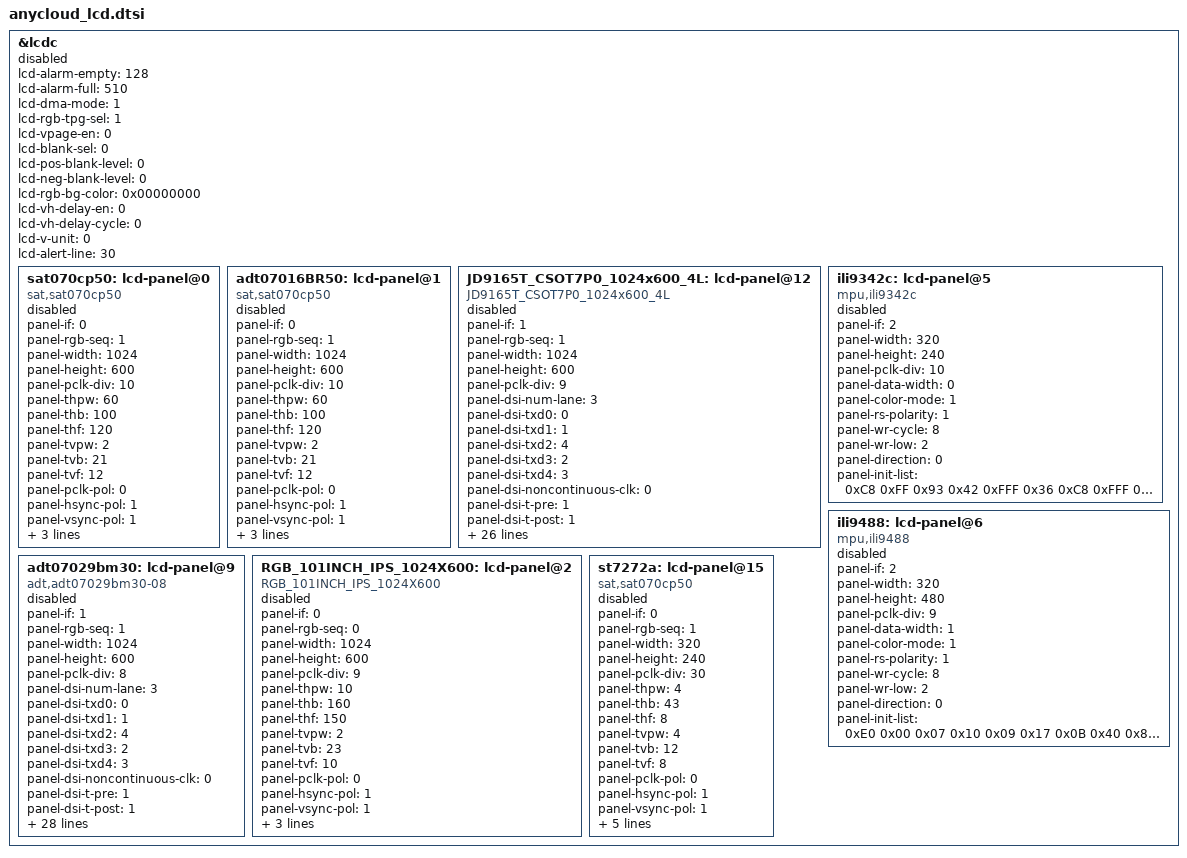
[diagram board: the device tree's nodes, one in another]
/*
 * Anycloud LCD panel dts
 *
 * Copyright (C) 2018 Anyka(Guangzhou) Microelectronics Technology Co., Ltd.
 *
 * Author: Feilong Dong <dong_feilong@anyka.com>
 *
 * This program is free software; you can redistribute it and/or modify
 * it under the terms of the GNU General Public License as published by
 * the Free Software Foundation; either version 2 of the License, or
 * (at your option) any later version.
 *
 * This program is distributed in the hope that it will be useful,
 * but WITHOUT ANY WARRANTY; without even the implied warranty of
 * MERCHANTABILITY or FITNESS FOR A PARTICULAR PURPOSE.  See the
 * GNU General Public License for more details.
 */

&lcdc {
    lcd-alarm-empty = <128>;
    lcd-alarm-full = <510>;
    lcd-dma-mode = <1>;
    //lcd-dummy-seq = <0>; //for 8bit rgb panel set
    //lcd-rgb-seq-sel = <0>;
    //lcd-rgb-odd-seq = <0>;
    //lcd-rgb-even-seq = <0>;
    lcd-rgb-tpg-sel = <1>;
    lcd-vpage-en = <0>; //don't support vpage function in driver
    lcd-blank-sel = <0>;
    lcd-pos-blank-level = <0>;
    lcd-neg-blank-level = <0>;
    lcd-rgb-bg-color = <0x00000000>;
    lcd-vh-delay-en = <0>;
    lcd-vh-delay-cycle = <0>;
    lcd-v-unit = <0>;
    lcd-alert-line = <30>;
    status = "disable";
    
    sat070cp50: lcd-panel@0 { //for RGB panel setting
        compatible = "sat,sat070cp50";
        panel-if = <0>; //0 for RGB, 1 for MIPI, 2 for MPU
        panel-rgb-seq = <1>; //0 for BGR, 1 for RGB
        panel-width = <1024>;
        panel-height = <600>;
        panel-pclk-div = <10>; //pixel clock = Peri_pll/(pclk_div+1)
        panel-thpw = <60>;
        panel-thb = <100>;
        panel-thf = <120>;
        panel-tvpw = <2>;
        panel-tvb = <21>;
        panel-tvf = <12>;
        panel-pclk-pol = <0>; //0:pos, 1:neg
        panel-hsync-pol = <1>;
        panel-vsync-pol = <1>;
        panel-vogate-pol = <0>;
        panel-bus-width = <3>; //0:8bits,1:16bits,2:18bits,3:24bits
        panel-sync-mode = <1>; 

        status = "disable";
    };

    adt07016BR50: lcd-panel@1 { //for AJB RGB panel setting
        compatible = "sat,sat070cp50";
        panel-if = <0>; //0 for RGB, 1 for MIPI, 2 for MPU
        panel-rgb-seq = <1>; //0 for BGR, 1 for RGB
        panel-width = <1024>;
        panel-height = <600>;
        panel-pclk-div = <10>; //pixel clock = Peri_pll/(pclk_div+1)
        panel-thpw = <60>;
        panel-thb = <100>;
        panel-thf = <120>;
        panel-tvpw = <2>;
        panel-tvb = <21>;
        panel-tvf = <12>;
        panel-pclk-pol = <0>; //0:pos, 1:neg
        panel-hsync-pol = <1>;
        panel-vsync-pol = <1>;
        panel-vogate-pol = <0>;
        panel-bus-width = <3>; //0:8bits,1:16bits,2:18bits,3:24bits
        panel-sync-mode = <1>; 

        status = "disable";
    };

    JD9165T_CSOT7P0_1024x600_4L: lcd-panel@12 {
        compatible = "JD9165T_CSOT7P0_1024x600_4L";
        panel-if = <1>; //0 for RGB, 1 for MIPI, 2 for MPU
        panel-rgb-seq = <1>; //0 for BGR, 1 for RGB
        panel-width = <1024>;
        panel-height = <600>;
        panel-pclk-div = <9>; //target pixel clock is about 52MHz when ASIC PLL is 520MHz
        panel-dsi-num-lane = <3>; //0-3: 1lane-4lane
        panel-dsi-txd0 = <0>;
        panel-dsi-txd1 = <1>;
        panel-dsi-txd2 = <4>;
        panel-dsi-txd3 = <2>;
        panel-dsi-txd4 = <3>;
        panel-dsi-noncontinuous-clk = <0>;
        panel-dsi-t-pre = <1>;
        panel-dsi-t-post = <1>;
        panel-dsi-tx-gap = <1>;
        panel-dsi-autoinsert-eotp = <0>;
        panel-dsi-htx-to-count = <0xFFFFFF>;
        panel-dsi-lrx-to-count = <0xFFFFFF>;
        panel-dsi-bta-to-count = <0xFFFFFF>;
        panel-dsi-t-wakeup = <0xc8>;
        panel-dsi-pix-fifo-send-level = <512>;
        panel-dsi-if-color-coding = <0x05>; //24-bit
        panel-dsi-pix-format = <0x03>; //24-bit
        panel-dsi-vsync-pol = <0>;
        panel-dsi-hsync-pol = <0>;
        panel-dsi-video-mode = <0>; //DSI non-burst mode with sync pulses
        panel-dsi-hfp = <100>;
        panel-dsi-hbp = <100>;
        panel-dsi-hsa = <2>;
        panel-dsi-mult-pkts-en = <0>;
        panel-dsi-vbp = <12>;
        panel-dsi-vfp = <95>;
        panel-dsi-vsa = <2>;
        panel-dsi-bllp-mode = <1>;
        panel-dsi-use-null-pkt-bllp = <0>;
        panel-dsi-vc = <0x00>;
        panel-dsi-cmd-type = <0x0>; //0:send init commands in LP mode
        panel-dsi-clk = <400>;
        panel-init-list =
                        <   0x00 0x39 0xDF 0x90 0x85 0x15 0xFFF
                            0x00 0x15 0xDE 0x00 0xFFF
                            0x00 0x15 0xCC 0x37 0xFFF
                            0x00 0x39 0xB2 0x00 0x50 0x50 0xFFF
                            0x00 0x39 0xB6 0x11 0x4F 0x00 0x5F 0x0D 0x16 0xC0 0xEE 0x00 0x5F 0x0D 0x8F 0xFFF
                            0x00 0x39 0xB7 0x00 0xBD 0xBD 0xFFF
                            0x00 0x39 0xBB 0x06 0x67 0x3F 0xFFF
                            0x00 0x39 0xC1 0x40 0x01 0x00 0xFFF
                            0x00 0x39 0xC3 0x0C 0x01 0x00 0x0C 0x18 0xE0 0x78 0x12 0xE8 0xFFF
                            0x00 0x39 0xC4 0x13 0x2C 0x00 0x00 0x00 0x00 0x00 0x00 0x00 0x03 0x22 0xFFF
                            0x00 0x39 0xC8 0x6E 0x69 0x64 0x57 0x4D 0x4E 0x3F 0x46 0x34 0x4E 0x4D 0x4C 0x67 0x54 0x5B 0x4C 0x4B 0x3F 0x2F 0x2B 0x27 0x6E 0x69 0x64 0x57 0x4D 0x4E 0x3F 0x46 0x34 0x4E 0x4D 0x4C 0x67 0x54 0x5B 0x4C 0x4B 0x3F 0x2F 0x2B 0x27 0xFFF
                            0x00 0x39 0xCB 0x71 0xC0 0x00 0xC0 0xC0 0xC0 0x00 0xCB 0x2A 0x00 0x00 0xFFF
                            0x00 0x39 0xCE 0x00 0x50 0x45 0x44 0x44 0x00 0x00 0x0C 0x00 0x00 0x00 0x00 0x00 0x50 0x45 0x44 0x44 0x00 0xFFF
                            0x00 0x39 0xCF 0x00 0x02 0x01 0x02 0x2C 0x02 0x7C 0x03 0x2C 0x00 0x00 0x05 0x7C 0x05 0x2C 0xFFF
                            0x00 0x39 0xD0 0x00 0xE5 0xE5 0xE5 0xE5 0xE5 0xE5 0xDF 0xC6 0xC6 0xD7 0xC4 0xC4 0xD8 0xCA 0xCA 0xE1 0xC8 0xC8 0xD5 0xE5 0xC0 0xDF 0xFFF
                            0x00 0x39 0xD1 0x00 0xE5 0xE5 0xE5 0xE5 0xE5 0xE5 0xDF 0xC7 0xC7 0xD7 0xC5 0xC5 0xD8 0xCB 0xCB 0xE1 0xC9 0xC9 0xD5 0xE5 0xC1 0xDF 0xFFF
                            0x00 0x39 0xD2 0x00 0x25 0x25 0x25 0x25 0x25 0x25 0x1F 0x09 0x09 0x17 0x0B 0x0B 0x18 0x05 0x05 0x21 0x07 0x07 0x1F 0x25 0x01 0x15 0xFFF
                            0x00 0x39 0xD3 0x00 0x25 0x25 0x25 0x25 0x25 0x25 0x1F 0x08 0x08 0x17 0x0A 0x0A 0x18 0x04 0x04 0x21 0x06 0x06 0x1F 0x25 0x00 0x15 0xFFF
                            0x00 0x39 0xD4 0x30 0x00 0x00 0x14 0x00 0x00 0x00 0x00 0x00 0x00 0x00 0x05 0x02 0x00 0x11 0x80 0x00 0xC0 0x04 0x00 0x00 0x00 0x00 0x00 0x00 0x00 0x01 0x01 0x11 0x80 0x0A 0xC0 0x05 0x07 0x01 0x00 0x0B 0x04 0x0A 0x04 0xC8 0xFFF
                            0x00 0x39 0xD5 0x02 0x14 0x01 0x00 0x00 0x00 0x00 0x00 0x00 0x72 0x00 0x17 0x08 0x71 0x00 0x04 0x18 0x1E 0x01 0x09 0x00 0x09 0xFFF
                            0x00 0x39 0xD6 0x04 0x02 0x04 0x02 0x04 0x04 0x04 0x04 0x04 0x02 0x04 0x04 0xFFF
                            0x00 0x15 0xDE 0x02 0xFFF
                            0x00 0x39 0xC5 0x4A 0x00 0xFFF
                            0x00 0x39 0xD0 0x00 0x00 0x11 0x00 0x11 0x26 0x4A 0xEC 0x10 0x59 0x8D 0x26 0x4A 0xEC 0x10 0x59 0x8D 0x00 0x66 0xDD 0x66 0xDD 0xEA 0x86 0x20 0xDC 0x95 0x41 0xEA 0x86 0x20 0xDC 0x95 0x41 0xFFF
                            0x00 0x39 0xD6 0x01 0x01 0x00 0x04 0x00 0x5A 0x00 0x03 0xFFF
                            0x00 0x15 0xDE 0x04 0xFFF
                            0x00 0x39 0xB0 0x44 0x01 0xFFF
                            0x00 0x15 0xDE 0x00 0xFFF
                            0x78 0x05 0x11 0x00 0xFFF
                            0x78 0x05 0x29 0x00 0xFFF>;
        status = "disable";
    };

    // sat101at40: lcd-panel@3 { //for JD9364 MIPI panel setting
    //     compatible = "sat,sat101at40";
    //     panel-if = <1>; //0 for RGB, 1 for MIPI, 2 for MPU
    //     panel-rgb-seq = <1>; //0 for BGR, 1 for RGB
    //     panel-width = <800>;
    //     panel-height = <1280>;
    //     panel-pclk-div = <8>; //pixel clock = Peri_pll/(pclk_div+1)
    //     panel-dsi-num-lane = <3>; //0-3: 1lane-4lane
    //     //0-3: data0-data3, 4: clk
    //     panel-dsi-txd0 = <2>;
    //     panel-dsi-txd1 = <1>;
    //     panel-dsi-txd2 = <4>;
    //     panel-dsi-txd3 = <0>;
    //     panel-dsi-txd4 = <3>;
    //     panel-dsi-noncontinuous-clk = <0>; //0:continuous,1:noncontinuous
    //     panel-dsi-t-pre = <1>; //t-pre, >=1
    //     panel-dsi-t-post = <1>; //t-post=tlpx+t-prepare+t-zero+t-pre, >=1
    //     panel-dsi-tx-gap = <1>; //ths-exit
    //     panel-dsi-autoinsert-eotp = <0>; //0:not insert,1:auto-insert
    //     panel-dsi-htx-to-count = <0xFFFFFF>; //high speed TX timeout count
    //     panel-dsi-lrx-to-count = <0xFFFFFF>; //Low power RX timeout count
    //     panel-dsi-bta-to-count = <0xFFFFFF>; //Bus turn around timeout count
    //     panel-dsi-t-wakeup = <0xc8>; //DPHY T-wakeup time
    //     panel-dsi-pix-fifo-send-level = <512>; //buffer send level <= 512
    //     //0-2:16-bit config 1-3; 3-4:18-bit config 1-2; 5:24-bit
    //     panel-dsi-if-color-coding = <0x05>;
    //     //0:16-bit;1:18-bit;2:18-bit loosely packed;3:24-bit
    //     panel-dsi-pix-format = <0x03>;
    //     panel-dsi-vsync-pol = <0>; //0:active low; 1:active high
    //     panel-dsi-hsync-pol = <0>; //0:active low; 1:active high
    //     //0:Non-burst mode with sync pulses;
    //     //1:Noe-burst mode with sync events;
    //     //2:Burst mode; 3:reserved
    //     panel-dsi-video-mode = <2>;
    //     panel-dsi-hfp = <32>; //H front porch blanking packet payload size in bytes
    //     panel-dsi-hbp = <8>; //H back porch blanking packet payload size in bytes
    //     panel-dsi-hsa = <8>; //H sync width blanking packet payload size in bytes
    //     panel-dsi-mult-pkts-en = <0>; //0: single packet;1: two packets
    //     panel-dsi-vbp = <8>; //V back porch lines
    //     panel-dsi-vfp = <30>; //V front porch lines
    //     panel-dsi-vsa = <4>;
    //     //0:blanking packets send during BLLP;1:LP mode used for BLLP
    //     panel-dsi-bllp-mode = <1>;
    //     panel-dsi-use-null-pkt-bllp = <0>; //0:blanking packet; 1:Null packet
    //     panel-dsi-vc = <0x00>; //Virtual channel
    //     panel-dsi-cmd-type = <0x0>; //0:send in LP mode, 1:send in HS mode
    //     panel-dsi-clk = <600>;
    //     //add special config list here
    //     panel-init-list = <0x00 0x23 0xE0 0x00 0xFFF
    //                         0x00 0x23 0xE1 0x93 0xFFF
    //                         0x00 0x23 0xE2 0x65 0xFFF
    //                         0x00 0x23 0xE3 0xF8 0xFFF
    //                         0x00 0x23 0x70 0x10 0xFFF
    //                         0x00 0x23 0x71 0x13 0xFFF
    //                         0x00 0x23 0x72 0x06 0xFFF
    //                         0x00 0x23 0x80 0x03 0xFFF
    //                         0x00 0x23 0xE0 0x04 0xFFF
    //                         0x00 0x23 0x2D 0x03 0xFFF
    //                         0x00 0x23 0xE0 0x01 0xFFF
    //                         0x00 0x23 0x00 0x00 0xFFF
    //                         0x00 0x23 0x01 0xB3 0xFFF
    //                         0x00 0x23 0x17 0x00 0xFFF
    //                         0x00 0x23 0x18 0xD8 0xFFF
    //                         0x00 0x23 0x19 0x05 0xFFF
    //                         0x00 0x23 0x1A 0x00 0xFFF
    //                         0x00 0x23 0x1B 0xD8 0xFFF
    //                         0x00 0x23 0x1C 0x05 0xFFF
    //                         0x00 0x23 0x1F 0x7E 0xFFF
    //                         0x00 0x23 0x20 0x28 0xFFF
    //                         0x00 0x23 0x21 0x28 0xFFF
    //                         0x00 0x23 0x22 0x0E 0xFFF
    //                         0x00 0x23 0x24 0xF8 0xFFF
    //                         0x00 0x23 0x26 0xF3 0xFFF
    //                         0x00 0x23 0x27 0x44 0xFFF
    //                         0x00 0x23 0x37 0x59 0xFFF
    //                         0x00 0x23 0x38 0x05 0xFFF
    //                         0x00 0x23 0x39 0x0C 0xFFF
    //                         0x00 0x23 0x3A 0x18 0xFFF
    //                         0x00 0x23 0x3C 0x78 0xFFF
    //                         0x00 0x23 0x3E 0x78 0xFFF
    //                         0x00 0x23 0x40 0x06 0xFFF
    //                         0x00 0x23 0x41 0xA0 0xFFF
    //                         0x00 0x23 0x55 0x01 0xFFF
    //                         0x00 0x23 0x56 0x01 0xFFF
    //                         0x00 0x23 0x57 0xA8 0xFFF
    //                         0x00 0x23 0x58 0x0A 0xFFF
    //                         0x00 0x23 0x59 0x2A 0xFFF
    //                         0x00 0x23 0x5A 0x3C 0xFFF
    //                         0x00 0x23 0x5B 0x14 0xFFF
    //                         0x00 0x23 0x5D 0x70 0xFFF
    //                         0x00 0x23 0x5E 0x53 0xFFF
    //                         0x00 0x23 0x5F 0x42 0xFFF
    //                         0x00 0x23 0x60 0x35 0xFFF
    //                         0x00 0x23 0x61 0x32 0xFFF
    //                         0x00 0x23 0x62 0x23 0xFFF
    //                         0x00 0x23 0x63 0x28 0xFFF
    //                         0x00 0x23 0x64 0x13 0xFFF
    //                         0x00 0x23 0x65 0x2D 0xFFF
    //                         0x00 0x23 0x66 0x2D 0xFFF
    //                         0x00 0x23 0x67 0x2D 0xFFF
    //                         0x00 0x23 0x68 0x4B 0xFFF
    //                         0x00 0x23 0x69 0x39 0xFFF
    //                         0x00 0x23 0x6A 0x40 0xFFF
    //                         0x00 0x23 0x6B 0x2F 0xFFF
    //                         0x00 0x23 0x6C 0x26 0xFFF
    //                         0x00 0x23 0x6D 0x1E 0xFFF
    //                         0x00 0x23 0x6E 0x07 0xFFF
    //                         0x00 0x23 0x6F 0x02 0xFFF
    //                         0x00 0x23 0x70 0x70 0xFFF
    //                         0x00 0x23 0x71 0x53 0xFFF
    //                         0x00 0x23 0x72 0x42 0xFFF
    //                         0x00 0x23 0x73 0x35 0xFFF
    //                         0x00 0x23 0x74 0x32 0xFFF
    //                         0x00 0x23 0x75 0x23 0xFFF
    //                         0x00 0x23 0x76 0x28 0xFFF
    //                         0x00 0x23 0x77 0x13 0xFFF
    //                         0x00 0x23 0x78 0x2D 0xFFF
    //                         0x00 0x23 0x79 0x2D 0xFFF
    //                         0x00 0x23 0x7A 0x2D 0xFFF
    //                         0x00 0x23 0x7B 0x4B 0xFFF
    //                         0x00 0x23 0x7C 0x39 0xFFF
    //                         0x00 0x23 0x7D 0x40 0xFFF
    //                         0x00 0x23 0x7E 0x2F 0xFFF
    //                         0x00 0x23 0x7F 0x26 0xFFF
    //                         0x00 0x23 0x80 0x1E 0xFFF
    //                         0x00 0x23 0x81 0x07 0xFFF
    //                         0x00 0x23 0x82 0x02 0xFFF
    //                         0x00 0x23 0xE0 0x02 0xFFF
    //                         0x00 0x23 0x00 0x53 0xFFF
    //                         0x00 0x23 0x01 0x5F 0xFFF
    //                         0x00 0x23 0x02 0x5F 0xFFF
    //                         0x00 0x23 0x03 0x5F 0xFFF
    //                         0x00 0x23 0x04 0x5F 0xFFF
    //                         0x00 0x23 0x05 0x51 0xFFF
    //                         0x00 0x23 0x06 0x58 0xFFF
    //                         0x00 0x23 0x07 0x57 0xFFF
    //                         0x00 0x23 0x08 0x4F 0xFFF
    //                         0x00 0x23 0x09 0x5F 0xFFF
    //                         0x00 0x23 0x0A 0x4D 0xFFF
    //                         0x00 0x23 0x0B 0x4B 0xFFF
    //                         0x00 0x23 0x0C 0x5F 0xFFF
    //                         0x00 0x23 0x0D 0x49 0xFFF
    //                         0x00 0x23 0x0E 0x47 0xFFF
    //                         0x00 0x23 0x0F 0x45 0xFFF
    //                         0x00 0x23 0x10 0x41 0xFFF
    //                         0x00 0x23 0x11 0x5F 0xFFF
    //                         0x00 0x23 0x12 0x5F 0xFFF
    //                         0x00 0x23 0x13 0x5F 0xFFF
    //                         0x00 0x23 0x14 0x5F 0xFFF
    //                         0x00 0x23 0x15 0x5F 0xFFF
    //                         0x00 0x23 0x16 0x52 0xFFF
    //                         0x00 0x23 0x17 0x5F 0xFFF
    //                         0x00 0x23 0x18 0x5F 0xFFF
    //                         0x00 0x23 0x19 0x5F 0xFFF
    //                         0x00 0x23 0x1A 0x5F 0xFFF
    //                         0x00 0x23 0x1B 0x50 0xFFF
    //                         0x00 0x23 0x1C 0x58 0xFFF
    //                         0x00 0x23 0x1D 0x57 0xFFF
    //                         0x00 0x23 0x1E 0x4E 0xFFF
    //                         0x00 0x23 0x1F 0x5F 0xFFF
    //                         0x00 0x23 0x20 0x4C 0xFFF
    //                         0x00 0x23 0x21 0x4A 0xFFF
    //                         0x00 0x23 0x22 0x5F 0xFFF
    //                         0x00 0x23 0x23 0x48 0xFFF
    //                         0x00 0x23 0x24 0x46 0xFFF
    //                         0x00 0x23 0x25 0x44 0xFFF
    //                         0x00 0x23 0x26 0x40 0xFFF
    //                         0x00 0x23 0x27 0x5F 0xFFF
    //                         0x00 0x23 0x28 0x5F 0xFFF
    //                         0x00 0x23 0x29 0x5F 0xFFF
    //                         0x00 0x23 0x2A 0x5F 0xFFF
    //                         0x00 0x23 0x2B 0x5F 0xFFF
    //                         0x00 0x23 0x2C 0x52 0xFFF
    //                         0x00 0x23 0x2D 0x5F 0xFFF
    //                         0x00 0x23 0x2E 0x5F 0xFFF
    //                         0x00 0x23 0x2F 0x5F 0xFFF
    //                         0x00 0x23 0x30 0x5F 0xFFF
    //                         0x00 0x23 0x31 0x40 0xFFF
    //                         0x00 0x23 0x32 0x58 0xFFF
    //                         0x00 0x23 0x33 0x57 0xFFF
    //                         0x00 0x23 0x34 0x44 0xFFF
    //                         0x00 0x23 0x35 0x5F 0xFFF
    //                         0x00 0x23 0x36 0x46 0xFFF
    //                         0x00 0x23 0x37 0x48 0xFFF
    //                         0x00 0x23 0x38 0x5F 0xFFF
    //                         0x00 0x23 0x39 0x4A 0xFFF
    //                         0x00 0x23 0x3A 0x4C 0xFFF
    //                         0x00 0x23 0x3B 0x4E 0xFFF
    //                         0x00 0x23 0x3C 0x50 0xFFF
    //                         0x00 0x23 0x3D 0x5F 0xFFF
    //                         0x00 0x23 0x3E 0x5F 0xFFF
    //                         0x00 0x23 0x3F 0x5F 0xFFF
    //                         0x00 0x23 0x40 0x5F 0xFFF
    //                         0x00 0x23 0x41 0x5F 0xFFF
    //                         0x00 0x23 0x42 0x53 0xFFF
    //                         0x00 0x23 0x43 0x5F 0xFFF
    //                         0x00 0x23 0x44 0x5F 0xFFF
    //                         0x00 0x23 0x45 0x5F 0xFFF
    //                         0x00 0x23 0x46 0x5F 0xFFF
    //                         0x00 0x23 0x47 0x41 0xFFF
    //                         0x00 0x23 0x48 0x58 0xFFF
    //                         0x00 0x23 0x49 0x57 0xFFF
    //                         0x00 0x23 0x4A 0x45 0xFFF
    //                         0x00 0x23 0x4B 0x5F 0xFFF
    //                         0x00 0x23 0x4C 0x47 0xFFF
    //                         0x00 0x23 0x4D 0x49 0xFFF
    //                         0x00 0x23 0x4E 0x5F 0xFFF
    //                         0x00 0x23 0x4F 0x4B 0xFFF
    //                         0x00 0x23 0x50 0x4D 0xFFF
    //                         0x00 0x23 0x51 0x4F 0xFFF
    //                         0x00 0x23 0x52 0x51 0xFFF
    //                         0x00 0x23 0x53 0x5F 0xFFF
    //                         0x00 0x23 0x54 0x5F 0xFFF
    //                         0x00 0x23 0x55 0x5F 0xFFF
    //                         0x00 0x23 0x56 0x5F 0xFFF
    //                         0x00 0x23 0x57 0x5F 0xFFF
    //                         0x00 0x23 0x58 0x10 0xFFF
    //                         0x00 0x23 0x59 0x00 0xFFF
    //                         0x00 0x23 0x5A 0x00 0xFFF
    //                         0x00 0x23 0x5B 0x10 0xFFF
    //                         0x00 0x23 0x5C 0x05 0xFFF
    //                         0x00 0x23 0x5D 0x30 0xFFF
    //                         0x00 0x23 0x5E 0x00 0xFFF
    //                         0x00 0x23 0x5F 0x00 0xFFF
    //                         0x00 0x23 0x60 0x30 0xFFF
    //                         0x00 0x23 0x61 0x02 0xFFF
    //                         0x00 0x23 0x62 0x00 0xFFF
    //                         0x00 0x23 0x63 0x03 0xFFF
    //                         0x00 0x23 0x64 0x7B 0xFFF
    //                         0x00 0x23 0x65 0x75 0xFFF
    //                         0x00 0x23 0x66 0x0B 0xFFF
    //                         0x00 0x23 0x67 0xB3 0xFFF
    //                         0x00 0x23 0x68 0x07 0xFFF
    //                         0x00 0x23 0x69 0x06 0xFFF
    //                         0x00 0x23 0x6A 0x7B 0xFFF
    //                         0x00 0x23 0x6B 0x04 0xFFF
    //                         0x00 0x23 0x6C 0x00 0xFFF
    //                         0x00 0x23 0x6D 0x04 0xFFF
    //                         0x00 0x23 0x6E 0x04 0xFFF
    //                         0x00 0x23 0x6F 0x88 0xFFF
    //                         0x00 0x23 0x70 0x00 0xFFF
    //                         0x00 0x23 0x71 0x00 0xFFF
    //                         0x00 0x23 0x72 0x06 0xFFF
    //                         0x00 0x23 0x73 0x7B 0xFFF
    //                         0x00 0x23 0x74 0x00 0xFFF
    //                         0x00 0x23 0x75 0x80 0xFFF
    //                         0x00 0x23 0x76 0x00 0xFFF
    //                         0x00 0x23 0x77 0x0D 0xFFF
    //                         0x00 0x23 0x78 0x2A 0xFFF
    //                         0x00 0x23 0x79 0x00 0xFFF
    //                         0x00 0x23 0x7A 0x00 0xFFF
    //                         0x00 0x23 0x7B 0x00 0xFFF
    //                         0x00 0x23 0x7C 0x00 0xFFF
    //                         0x00 0x23 0x7D 0x03 0xFFF
    //                         0x00 0x23 0x7E 0x7B 0xFFF
    //                         0x00 0x23 0xE0 0x00 0xFFF
    //                         0x78 0x13 0x11 0x00 0xFFF
    //                         0x05 0x13 0x29 0x00 0xFFF
    //                         0x78 0x23 0x35 0x00 0xFFF>;

    //     status = "disable";
    // };

    ili9342c: lcd-panel@5 {
        compatible = "mpu,ili9342c";
        panel-if = <2>;//0 for RGB, 1 for MIPI, 2 for MPU
        panel-width = <320>;
        panel-height = <240>;
        panel-pclk-div = <10>; //default pixel clock = Peri_pll(600M)/(pclk_div+1)=60M
        panel-data-width = <0>; //0:8bits,1:16bits,2:18bits,3:9bits
        panel-color-mode = <1>; //0:4K 1:64K/256K
        panel-rs-polarity = <1>; //0:negative(0 means data while 1 means command)
                                //1:positive(0 means command while 1 means data)
        panel-wr-cycle = <8>; // write timing setting, wr-cycle >= 4*(wr-low) (8/9bits mode)
        panel-wr-low = <2>; // write timing setting,wr_cycle_len/2 - wr_low_len >= 2 (8/9bits mode)

        /* 0 for portrait, 1 for landscape*/
        panel-direction = <0>; 

    panel-init-list = <0xC8 0xFF 0x93 0x42 0xFFF
                             0x36 0xC8 0xFFF
                             0x3A 0x55 0xFFF
                             0xC0 0x13 0x0E 0xFFF
                             0xC1 0x02 0xFFF
                             0xC5 0xD5 0xFFF
                             0xB1 0x00 0x1B 0xFFF
                             0xB4 0x02 0xFFF
                             0xE0 0x00 0x07 0x0C 0x06
                             0x15 0x09 0x3A 0x36 0x48
                             0x02 0x0B 0x0A 0x15 0x16
                             0x0F 0xFFF
                             0xE1 0x00 0x25 0x26 0x02
                             0x0E 0x03 0x3D 0x13 0x4E
                             0x03 0x0E 0x0B 0x34 0x37
                             0x0F 0xFFF
                             0x11 0xFFF
                             0x29 0xFFF>;
        status = "disable";
    };

    ili9488: lcd-panel@6 {
		compatible = "mpu,ili9488";
		panel-if = <2>;//0 for RGB, 1 for MIPI, 2 for MPU
		panel-width = <320>;
		panel-height = <480>;
		panel-pclk-div = <9>; //default pixel clock = Peri_pll(600M)/(pclk_div+1)=60M
		panel-data-width = <1>; //0:8bits,1:16bits,2:18bits,3:9bits
		panel-color-mode = <1>; //0:4K 1:64K/256K
		panel-rs-polarity = <1>; //0:negative(0 means data while 1 means command)
								//1:positive(0 means command while 1 means data)
		panel-wr-cycle = <8>; // write timing setting, wr-cycle >= 4*(wr-low) (8/9bits mode)
		panel-wr-low = <2>; // write timing setting,wr_cycle_len/2 - wr_low_len >= 2 (8/9bits mode)

    /* 0 for portrait, 1 for landscape*/
		panel-direction = <0>;

		panel-init-list = <0xE0 0x00 0x07 0x10 0x09
						   0x17 0x0B 0x40 0x8A 0x4B
						   0x0A 0x0D 0x0F 0x15 0x16
                           0x0F 0xFFF
                           0xE1 0x00 0x1A 0x1B 0x02
						   0x0D 0x05 0x30 0x35 0x43
						   0x02 0x0A 0x09 0x32 0x36
						   0x0F 0xFFF
						   0xB1 0xA0 0xFFF
						   0xB4 0x02 0xFFF
						   0xC0 0x17 0x15 0xFFF
						   0xC1 0x41 0xFFF
						   0xC5 0x00 0x30 0x80 0xFFF
						   0xB6 0x02 0xFFF
						   0x36 0x48 0xFFF
						   0x3A 0x55 0xFFF
						   0xE9 0x00 0xFFF
						   0xF7 0xA9 0x51 0x2C 0x82 0xFFF
						   0x11 0xFFF
 						   0x29 0xFFF>;

 	    status = "disable";
    };

	adt07029bm30: lcd-panel@9{ //for AJB 7.0 inch MIPI panel setting
            compatible = "adt,adt07029bm30-08";
            panel-if = <1>; //0 for RGB, 1 for MIPI, 2 for MPU
            panel-rgb-seq = <1>; //0 for BGR, 1 for RGB
            panel-width = <1024>;
            panel-height = <600>;
            panel-pclk-div = <8>; //pixel clock = Peri_pll/(pclk_div+1)
            panel-dsi-num-lane = <3>; //0-3: 1lane-4lane
            //0-3: data0-data3, 4: clk
            panel-dsi-txd0 = <0>;
            panel-dsi-txd1 = <1>;
            panel-dsi-txd2 = <4>;
            panel-dsi-txd3 = <2>;
            panel-dsi-txd4 = <3>;
            panel-dsi-noncontinuous-clk = <0>; //0:continuous,1:noncontinuous
            panel-dsi-t-pre = <1>; //t-pre, >=1
            panel-dsi-t-post = <1>; //t-post=tlpx+t-prepare+t-zero+t-pre, >=1
            panel-dsi-tx-gap = <1>; //ths-exit
            panel-dsi-autoinsert-eotp = <0>; //0:not insert,1:auto-insert
            panel-dsi-htx-to-count = <0xFFFFFF>; //high speed TX timeout count
            panel-dsi-lrx-to-count = <0xFFFFFF>; //Low power RX timeout count
            panel-dsi-bta-to-count = <0xFFFFFF>; //Bus turn around timeout count
            panel-dsi-t-wakeup = <0xc8>; //DPHY T-wakeup time
            panel-dsi-pix-fifo-send-level = <512>; //buffer send level <= 512
            //0-2:16-bit config 1-3; 3-4:18-bit config 1-2; 5:24-bit
            panel-dsi-if-color-coding = <0x05>;
            //0:16-bit;1:18-bit;2:18-bit loosely packed;3:24-bit
            panel-dsi-pix-format = <0x03>;
            panel-dsi-vsync-pol = <0>; //0:active low; 1:active high
            panel-dsi-hsync-pol = <0>; //0:active low; 1:active high
            //0:Non-burst mode with sync pulses;
            //1:Noe-burst mode with sync events;
            //2:Burst mode; 3:reserved
            panel-dsi-video-mode = <2>;
            panel-dsi-hfp = <40>; //H front porch blanking packet payload size in bytes
            panel-dsi-hbp = <20>; //H back porch blanking packet payload size in bytes
            panel-dsi-hsa = <20>; //H sync width blanking packet payload size in bytes
            panel-dsi-mult-pkts-en = <0>; //0: single packet;1: two packets
            panel-dsi-vbp = <8>; //V back porch lines
            panel-dsi-vfp = <8>; //V front porch lines
            panel-dsi-vsa = <4>;
            //0:blanking packets send during BLLP;1:LP mode used for BLLP
            panel-dsi-bllp-mode = <1>;
            panel-dsi-use-null-pkt-bllp = <0>; //0:blanking packet; 1:Null packet
            panel-dsi-vc = <0x00>; //Virtual channel
            panel-dsi-cmd-type = <0x0>; //0:send in LP mode, 1:send in HS mode
            panel-dsi-clk = <600>;
            //add special config list here
            panel-init-list-count = <50>;
            panel-init-list-line = <10>;
            panel-init-list =  //delay, type, data, parameters, end symbol
                            < 0x00 0x15 0x00 0x01 0xFFF
                              0x1E 0x15 0x00 0x00 0xFFF
                              0x00 0x15 0x8B 0x80 0xFFF
                              0x00 0x15 0x8B 0x80 0xFFF
                              0x00 0x15 0xFF 0x81 0xFFF
                              0x00 0x15 0x3C 0x82 0xFFF
                              0x00 0x15 0xFF 0x83 0xFFF
                              0x00 0x15 0xCA 0x84 0xFFF
                              0x00 0x15 0xAF 0x85 0xFFF
                              0x00 0x15 0xB5 0x86 0xFFF>;
        status = "disable";
    };

    // MIPI_5INCH_IPS_720X1280: lcd-panel@2 { //for JD9364 MIPI panel setting
    //     compatible = "MIPI_5INCH_IPS_720X1280";
    //     panel-if = <1>; //0 for RGB, 1 for MIPI, 2 for MPU
    //     panel-rgb-seq = <1>; //0 for BGR, 1 for RGB
    //     panel-width = <720>;
    //     panel-height = <1280>;
    //     panel-pclk-div = <11>; //pixel clock = Peri_pll/(pclk_div+1)
    //     panel-dsi-num-lane = <1>; //0-3: 1lane-4lane
    //     //0-3: data0-data3, 4: clk
    //     panel-dsi-txd0 = <0>;
    //     panel-dsi-txd1 = <1>;
    //     panel-dsi-txd2 = <4>;
    //     panel-dsi-txd3 = <2>;
    //     panel-dsi-txd4 = <3>;
    //     panel-dsi-noncontinuous-clk = <1>; //0:continuous,1:noncontinuous
    //     panel-dsi-t-pre = <1>; //t-pre, >=1
    //     panel-dsi-t-post = <1>; //t-post=tlpx+t-prepare+t-zero+t-pre, >=1
    //     panel-dsi-tx-gap = <1>; //ths-exit
    //     panel-dsi-autoinsert-eotp = <0>; //0:not insert,1:auto-insert
    //     panel-dsi-htx-to-count = <0xFFFFFF>; //high speed TX timeout count
    //     panel-dsi-lrx-to-count = <0xFFFFFF>; //Low power RX timeout count
    //     panel-dsi-bta-to-count = <0xFFFFFF>; //Bus turn around timeout count
    //     panel-dsi-t-wakeup = <0xc8>; //DPHY T-wakeup time
    //     panel-dsi-pix-fifo-send-level = <512>; //buffer send level <= 512
    //     //0-2:16-bit config 1-3; 3-4:18-bit config 1-2; 5:24-bit
    //     panel-dsi-if-color-coding = <0x05>;
    //     //0:16-bit;1:18-bit;2:18-bit loosely packed;3:24-bit
    //     panel-dsi-pix-format = <0x03>;
    //     panel-dsi-vsync-pol = <0>; //0:active low; 1:active high
    //     panel-dsi-hsync-pol = <0>; //0:active low; 1:active high
    //     //0:Non-burst mode with sync pulses;
    //     //1:Noe-burst mode with sync events;
    //     //2:Burst mode; 3:reserved
    //     panel-dsi-video-mode = <1>;
    //     panel-dsi-hfp = <12>; //H front porch blanking packet payload size in bytes
    //     panel-dsi-hbp = <8>; //H back porch blanking packet payload size in bytes
    //     panel-dsi-hsa = <4>; //H sync width blanking packet payload size in bytes
    //     panel-dsi-mult-pkts-en = <0>; //0: single packet;1: two packets
    //     panel-dsi-vbp = <15>; //V back porch lines
    //     panel-dsi-vfp = <12>; //V front porch lines
    //     panel-dsi-vsa = <4>;
    //     //0:blanking packets send during BLLP;1:LP mode used for BLLP
    //     panel-dsi-bllp-mode = <1>;
    //     panel-dsi-use-null-pkt-bllp = <0>; //0:blanking packet; 1:Null packet
    //     panel-dsi-vc = <0x00>; //Virtual channel
    //     panel-dsi-cmd-type = <0x0>; //0:send in LP mode, 1:send in HS mode
    //     panel-dsi-clk = <1000>;
    //     /*add special config list here*/
    //     panel-init-list = <  
    //         0x00 0x15 0xE0 0x00 0xFFF
    //         0x00 0x15 0xE1 0x93 0xFFF
    //         0x00 0x15 0xE2 0x65 0xFFF
    //         0x00 0x15 0xE3 0xF8 0xFFF
    //         0x00 0x15 0x80 0x01 0xFFF
    //         0x00 0x15 0xE0 0x01 0xFFF
    //         0x00 0x15 0x00 0x00 0xFFF
    //         0x00 0x15 0x01 0xA6 0xFFF
    //         0x00 0x15 0x03 0x10 0xFFF
    //         0x00 0x15 0x04 0xB4 0xFFF
    //         0x00 0x15 0x0C 0x74 0xFFF
    //         0x00 0x15 0x17 0x00 0xFFF
    //         0x00 0x15 0x18 0xF7 0xFFF
    //         0x00 0x15 0x19 0x00 0xFFF
    //         0x00 0x15 0x1A 0x00 0xFFF
    //         0x00 0x15 0x1B 0xF7 0xFFF
    //         0x00 0x15 0x1C 0x00 0xFFF
    //         0x00 0x15 0x24 0xFE 0xFFF
    //         0x00 0x15 0x37 0x09 0xFFF
    //         0x00 0x15 0x38 0x04 0xFFF
    //         0x00 0x15 0x39 0x08 0xFFF
    //         0x00 0x15 0x3A 0x1A 0xFFF
    //         0x00 0x15 0x3B 0x18 0xFFF
    //         0x00 0x15 0x3C 0x6F 0xFFF
    //         0x00 0x15 0x3D 0xFF 0xFFF
    //         0x00 0x15 0x3E 0xFF 0xFFF
    //         0x00 0x15 0x3F 0xFF 0xFFF
    //         0x00 0x15 0x40 0x04 0xFFF
    //         0x00 0x15 0x41 0xA0 0xFFF
    //         0x00 0x15 0x43 0x08 0xFFF
    //         0x00 0x15 0x44 0x0A 0xFFF
    //         0x00 0x15 0x45 0x14 0xFFF
    //         0x00 0x15 0x55 0x02 0xFFF
    //         0x00 0x15 0x57 0x69 0xFFF
    //         0x00 0x15 0x58 0x0A 0xFFF
    //         0x00 0x15 0x59 0x0A 0xFFF
    //         0x00 0x15 0x5A 0x28 0xFFF
    //         0x00 0x15 0x5B 0x10 0xFFF
    //         0x00 0x15 0x5D 0x7F 0xFFF
    //         0x00 0x15 0x5E 0x5D 0xFFF
    //         0x00 0x15 0x5F 0x51 0xFFF
    //         0x00 0x15 0x60 0x48 0xFFF
    //         0x00 0x15 0x61 0x47 0xFFF
    //         0x00 0x15 0x62 0x3B 0xFFF
    //         0x00 0x15 0x64 0x2C 0xFFF
    //         0x00 0x15 0x65 0x45 0xFFF
    //         0x00 0x15 0x66 0x44 0xFFF
    //         0x00 0x15 0x67 0x44 0xFFF
    //         0x00 0x15 0x68 0x62 0xFFF
    //         0x00 0x15 0x69 0x50 0xFFF
    //         0x00 0x15 0x6A 0x57 0xFFF
    //         0x00 0x15 0x6B 0x49 0xFFF
    //         0x00 0x15 0x6C 0x43 0xFFF
    //         0x00 0x15 0x6D 0x34 0xFFF
    //         0x00 0x15 0x6E 0x20 0xFFF
    //         0x00 0x15 0x6F 0x01 0xFFF
    //         0x00 0x15 0x70 0x5C 0xFFF
    //         0x00 0x15 0x71 0x5D 0xFFF
    //         0x00 0x15 0x72 0x51 0xFFF
    //         0x00 0x15 0x73 0x48 0xFFF
    //         0x00 0x15 0x74 0x47 0xFFF
    //         0x00 0x15 0x75 0x3B 0xFFF
    //         0x00 0x15 0x76 0x40 0xFFF
    //         0x00 0x15 0x77 0x2C 0xFFF
    //         0x00 0x15 0x78 0x45 0xFFF
    //         0x00 0x15 0x79 0x44 0xFFF
    //         0x00 0x15 0x7A 0x44 0xFFF
    //         0x00 0x15 0x7B 0x62 0xFFF
    //         0x00 0x15 0x7C 0x50 0xFFF
    //         0x00 0x15 0x7D 0x57 0xFFF
    //         0x00 0x15 0x7E 0x49 0xFFF
    //         0x00 0x15 0x7F 0x43 0xFFF
    //         0x00 0x15 0x80 0x34 0xFFF
    //         0x00 0x15 0x81 0x20 0xFFF
    //         0x00 0x15 0x82 0x01 0xFFF
    //         0x00 0x15 0xE0 0x02 0xFFF
    //         0x00 0x15 0x00 0x1E 0xFFF
    //         0x00 0x15 0x01 0x1F 0xFFF
    //         0x00 0x15 0x02 0x17 0xFFF
    //         0x00 0x15 0x03 0x18 0xFFF
    //         0x00 0x15 0x04 0x48 0xFFF
    //         0x00 0x15 0x05 0x4A 0xFFF
    //         0x00 0x15 0x06 0x44 0xFFF
    //         0x00 0x15 0x07 0x46 0xFFF
    //         0x00 0x15 0x08 0x00 0xFFF
    //         0x00 0x15 0x09 0x1F 0xFFF
    //         0x00 0x15 0x0A 0x02 0xFFF
    //         0x00 0x15 0x0B 0x1F 0xFFF
    //         0x00 0x15 0x0C 0x1F 0xFFF
    //         0x00 0x15 0x0D 0x1F 0xFFF
    //         0x00 0x15 0x0E 0x1F 0xFFF
    //         0x00 0x15 0x0F 0x1F 0xFFF
    //         0x00 0x15 0x10 0x1F 0xFFF
    //         0x00 0x15 0x11 0x1F 0xFFF
    //         0x00 0x15 0x12 0x1F 0xFFF
    //         0x00 0x15 0x13 0x1F 0xFFF
    //         0x00 0x15 0x14 0x1F 0xFFF
    //         0x00 0x15 0x15 0x1F 0xFFF
    //         0x00 0x15 0x16 0x1E 0xFFF
    //         0x00 0x15 0x17 0x1F 0xFFF
    //         0x00 0x15 0x18 0x17 0xFFF
    //         0x00 0x15 0x19 0x18 0xFFF
    //         0x00 0x15 0x1A 0x49 0xFFF
    //         0x00 0x15 0x1B 0x4B 0xFFF
    //         0x00 0x15 0x1C 0x45 0xFFF
    //         0x00 0x15 0x1D 0x47 0xFFF
    //         0x00 0x15 0x1E 0x01 0xFFF
    //         0x00 0x15 0x1F 0x1F 0xFFF
    //         0x00 0x15 0x20 0x03 0xFFF
    //         0x00 0x15 0x21 0x1F 0xFFF
    //         0x00 0x15 0x22 0x1F 0xFFF
    //         0x00 0x15 0x23 0x1F 0xFFF
    //         0x00 0x15 0x24 0x1F 0xFFF
    //         0x00 0x15 0x25 0x1F 0xFFF
    //         0x00 0x15 0x26 0x1F 0xFFF
    //         0x00 0x15 0x27 0x1F 0xFFF
    //         0x00 0x15 0x28 0x1F 0xFFF
    //         0x00 0x15 0x29 0x1F 0xFFF
    //         0x00 0x15 0x2A 0x1F 0xFFF
    //         0x00 0x15 0x2B 0x1F 0xFFF
    //         0x00 0x15 0x2C 0x1F 0xFFF
    //         0x00 0x15 0x2D 0x1E 0xFFF
    //         0x00 0x15 0x2E 0x17 0xFFF
    //         0x00 0x15 0x2F 0x18 0xFFF
    //         0x00 0x15 0x30 0x47 0xFFF
    //         0x00 0x15 0x31 0x45 0xFFF
    //         0x00 0x15 0x32 0x4B 0xFFF
    //         0x00 0x15 0x33 0x49 0xFFF
    //         0x00 0x15 0x34 0x03 0xFFF
    //         0x00 0x15 0x35 0x1F 0xFFF
    //         0x00 0x15 0x36 0x01 0xFFF
    //         0x00 0x15 0x37 0x1F 0xFFF
    //         0x00 0x15 0x38 0x1F 0xFFF
    //         0x00 0x15 0x39 0x1F 0xFFF
    //         0x00 0x15 0x3A 0x1F 0xFFF
    //         0x00 0x15 0x3B 0x1F 0xFFF
    //         0x00 0x15 0x3C 0x1F 0xFFF
    //         0x00 0x15 0x3D 0x1F 0xFFF
    //         0x00 0x15 0x3E 0x1F 0xFFF
    //         0x00 0x15 0x3F 0x1F 0xFFF
    //         0x00 0x15 0x40 0x1F 0xFFF
    //         0x00 0x15 0x41 0x1F 0xFFF
    //         0x00 0x15 0x42 0x1F 0xFFF
    //         0x00 0x15 0x43 0x1E 0xFFF
    //         0x00 0x15 0x44 0x17 0xFFF
    //         0x00 0x15 0x45 0x18 0xFFF
    //         0x00 0x15 0x46 0x46 0xFFF
    //         0x00 0x15 0x47 0x44 0xFFF
    //         0x00 0x15 0x48 0x4A 0xFFF
    //         0x00 0x15 0x49 0x48 0xFFF
    //         0x00 0x15 0x4A 0x02 0xFFF
    //         0x00 0x15 0x4B 0x1F 0xFFF
    //         0x00 0x15 0x4C 0x00 0xFFF
    //         0x00 0x15 0x4D 0x1F 0xFFF
    //         0x00 0x15 0x4E 0x1F 0xFFF
    //         0x00 0x15 0x4F 0x1F 0xFFF
    //         0x00 0x15 0x50 0x1F 0xFFF
    //         0x00 0x15 0x51 0x1F 0xFFF
    //         0x00 0x15 0x52 0x1F 0xFFF
    //         0x00 0x15 0x53 0x1F 0xFFF
    //         0x00 0x15 0x54 0x1F 0xFFF
    //         0x00 0x15 0x55 0x1F 0xFFF
    //         0x00 0x15 0x56 0x1F 0xFFF
    //         0x00 0x15 0x57 0x1F 0xFFF
    //         0x00 0x15 0x58 0x40 0xFFF
    //         0x00 0x15 0x59 0x00 0xFFF
    //         0x00 0x15 0x5A 0x00 0xFFF
    //         0x00 0x15 0x5B 0x30 0xFFF
    //         0x00 0x15 0x5C 0x00 0xFFF
    //         0x00 0x15 0x5D 0x30 0xFFF
    //         0x00 0x15 0x5E 0x01 0xFFF
    //         0x00 0x15 0x5F 0x02 0xFFF
    //         0x00 0x15 0x63 0x14 0xFFF
    //         0x00 0x15 0x64 0x64 0xFFF
    //         0x00 0x15 0x65 0x45 0xFFF
    //         0x00 0x15 0x67 0x73 0xFFF
    //         0x00 0x15 0x68 0x04 0xFFF
    //         0x00 0x15 0x69 0x04 0xFFF
    //         0x00 0x15 0x6A 0x56 0xFFF
    //         0x00 0x15 0x6B 0x08 0xFFF
    //         0x00 0x15 0x6C 0x00 0xFFF
    //         0x00 0x15 0x6D 0x06 0xFFF
    //         0x00 0x15 0x6E 0x06 0xFFF
    //         0x00 0x15 0x6F 0x88 0xFFF
    //         0x00 0x15 0x70 0x00 0xFFF
    //         0x00 0x15 0x71 0x00 0xFFF
    //         0x00 0x15 0x72 0x06 0xFFF
    //         0x00 0x15 0x73 0x7B 0xFFF
    //         0x00 0x15 0x74 0x00 0xFFF
    //         0x00 0x15 0x75 0xBC 0xFFF
    //         0x00 0x15 0x76 0x00 0xFFF
    //         0x00 0x15 0x77 0x3D 0xFFF
    //         0x00 0x15 0x78 0xA4 0xFFF
    //         0x00 0x15 0x88 0x14 0xFFF
    //         0x00 0x15 0xE0 0x04 0xFFF
    //         0x00 0x15 0x02 0x23 0xFFF
    //         0x00 0x15 0x09 0x10 0xFFF
    //         0x00 0x15 0x2C 0x6B 0xFFF
    //         0x00 0x15 0xE0 0x00 0xFFF
    //         0x78 0x05 0x11 0xFFF
    //         0x05 0x05 0x29 0xFFF
    //         0x00 0x15 0x35 0x00 0xFFF>;
    //     status = "disable";
    // };

    // MIPI_55INCH_IPS_720X1280: lcd-panel@2 { //for JD9364 MIPI panel setting
    //     compatible = "MIPI_55INCH_IPS_720X1280";
    //     panel-if = <1>; //0 for RGB, 1 for MIPI, 2 for MPU
    //     panel-rgb-seq = <1>; //0 for BGR, 1 for RGB
    //     panel-width = <720>;
    //     panel-height = <1280>;
    //     panel-pclk-div = <7>; //pixel clock = Peri_pll/(pclk_div+1)
    //     panel-dsi-num-lane = <3>; //0-3: 1lane-4lane
    //     //0-3: data0-data3, 4: clk
    //     panel-dsi-txd0 = <0>;
    //     panel-dsi-txd1 = <1>;
    //     panel-dsi-txd2 = <4>;
    //     panel-dsi-txd3 = <2>;
    //     panel-dsi-txd4 = <3>;
    //     panel-dsi-noncontinuous-clk = <1>; //0:continuous,1:noncontinuous
    //     panel-dsi-t-pre = <1>; //t-pre, >=1
    //     panel-dsi-t-post = <1>; //t-post=tlpx+t-prepare+t-zero+t-pre, >=1
    //     panel-dsi-tx-gap = <1>; //ths-exit
    //     panel-dsi-autoinsert-eotp = <0>; //0:not insert,1:auto-insert
    //     panel-dsi-htx-to-count = <0xFFFFFF>; //high speed TX timeout count
    //     panel-dsi-lrx-to-count = <0xFFFFFF>; //Low power RX timeout count
    //     panel-dsi-bta-to-count = <0xFFFFFF>; //Bus turn around timeout count
    //     panel-dsi-t-wakeup = <0xc8>; //DPHY T-wakeup time
    //     panel-dsi-pix-fifo-send-level = <512>; //buffer send level <= 512
    //     //0-2:16-bit config 1-3; 3-4:18-bit config 1-2; 5:24-bit
    //     panel-dsi-if-color-coding = <0x05>;
    //     //0:16-bit;1:18-bit;2:18-bit loosely packed;3:24-bit
    //     panel-dsi-pix-format = <0x03>;
    //     panel-dsi-vsync-pol = <0>; //0:active low; 1:active high
    //     panel-dsi-hsync-pol = <0>; //0:active low; 1:active high
    //     //0:Non-burst mode with sync pulses;
    //     //1:Noe-burst mode with sync events;
    //     //2:Burst mode; 3:reserved
    //     panel-dsi-video-mode = <1>;
    //     panel-dsi-hfp = <20>; //H front porch blanking packet payload size in bytes
    //     panel-dsi-hbp = <30>; //H back porch blanking packet payload size in bytes
    //     panel-dsi-hsa = <20>; //H sync width blanking packet payload size in bytes
    //     panel-dsi-mult-pkts-en = <0>; //0: single packet;1: two packets
    //     panel-dsi-vbp = <12>; //V back porch lines
    //     panel-dsi-vfp = <12>; //V front porch lines
    //     panel-dsi-vsa = <2>;
    //     //0:blanking packets send during BLLP;1:LP mode used for BLLP
    //     panel-dsi-bllp-mode = <1>;
    //     panel-dsi-use-null-pkt-bllp = <0>; //0:blanking packet; 1:Null packet
    //     panel-dsi-vc = <0x00>; //Virtual channel
    //     panel-dsi-cmd-type = <0x0>; //0:send in LP mode, 1:send in HS mode
    //     panel-dsi-clk = <540>;
    //     /*add special config list here*/
    //     panel-init-list = <  
    //         0x00 0x39 0xB9 0xFF 0x83 0x94 0xFFF
    //         0x00 0x39 0xBA 0x63 0x03 0x68 0x6B 0xB2 0xC0 0xFFF
    //         0x00 0x39 0xB1 0x48 0x12 0x72 0x09 0x32 0x54 0x71 0x71 0x57 0x47 0xFFF
    //         0x00 0x39 0xB2 0x00 0x80 0x64 0x0C 0x0D 0x2F 0xFFF
    //         0x00 0x39 0xB4 0x73 0x74 0x73 0x74 0x73 0x74 0x01 0x0C 0x86 0x75 0x00 0x3F 0x73 0x74 0x73 0x74 0x73 0x74 0x01 0x0C 0x86 0xFFF
    //         0x00 0x39 0xB6 0x5A 0x5A 0xFFF
    //         0x00 0x39 0xD3 0x00 0x00 0x07 0x07 0x40 0x07 0x0C 0x00 0x08 0x10 0x08 0x00 0x08 0x54 0x15 0x0A 0x05 0x0A 0x02 0x15 0x06 0x05 0x06 0x47 0x44 0x0A 0x0A 0x4B 0x10 0x07 0x07 0x0C 0x40 0xFFF
    //         0x00 0x39 0xD5 0x1C 0x1C 0x1D 0x1D 0x00 0x01 0x02 0x03 0x04 0x05 0x06 0x07 0x08 0x09 0x0A 0x0B 0x24 0x25 0x18 0x18 0x26 0x27 0x18 0x18 0x18 0x18 0x18 0x18 0x18 0x18 0x18 0x18 0x18 0x18 0x18 0x18 0x18 0x18 0x20 0x21 0x18 0x18 0x18 0x18 0xFFF
    //         0x00 0x39 0xD6 0x1C 0x1C 0x1D 0x1D 0x07 0x06 0x05 0x04 0x03 0x02 0x01 0x00 0x0B 0x0A 0x09 0x08 0x21 0x20 0x18 0x18 0x27 0x26 0x18 0x18 0x18 0x18 0x18 0x18 0x18 0x18 0x18 0x18 0x18 0x18 0x18 0x18 0x18 0x18 0x25 0x24 0x18 0x18 0x18 0x18 0xFFF
    //         0x00 0x39 0xE0 0x00 0x0A 0x15 0x1B 0x1E 0x21 0x24 0x22 0x47 0x56 0x65 0x66 0x6E 0x82 0x88 0x8B 0x9A 0x9D 0x98 0xA8 0xB9 0x5D 0x5C 0x61 0x66 0x6A 0x6F 0x7F 0x7F 0x00 0x0A 0x15 0x1B 0x1E 0x21 0x24 0x22 0x47 0x56 0x65 0x65 0x6E 0x81 0x87 0x8B 0x98 0x9D 0x99 0xA8 0xBA 0x5D 0x5D 0x62 0x67 0x6B 0x72 0x7F 0x7F 0xFFF
    //         0x00 0x39 0xC0 0x1F 0x31 0xFFF
    //         0x00 0x15 0xCC 0x0B 0xFFF
    //         0x00 0x15 0xD4 0x02 0xFFF
    //         0x00 0x15 0xBD 0x02 0xFFF
    //         0x00 0x39 0xD8 0xFF 0xFF 0xFF 0xFF 0xFF 0xFF 0xFF 0xFF 0xFF 0xFF 0xFF 0xFF 0xFFF
    //         0x00 0x15 0xBD 0x00 0xFFF
    //         0x00 0x15 0xBD 0x01 0xFFF
    //         0x00 0x15 0xB1 0x00 0xFFF
    //         0x00 0x15 0xBD 0x00 0xFFF
    //         0x00 0x15 0xC6 0xED 0xFFF
    //         0x96 0x05 0x11 0xFFF
    //         0x32 0x05 0x29 0xFFF>;
    //     status = "disable";
    // };

    // MIPI_4INCH_IPS_480X480: lcd-panel@2 { //for JD9364 MIPI panel setting
    //     compatible = "MIPI_4INCH_IPS_480X480";
    //     panel-if = <1>; //0 for RGB, 1 for MIPI, 2 for MPU
    //     panel-rgb-seq = <1>; //0 for BGR, 1 for RGB
    //     panel-width = <480>;
    //     panel-height = <480>;
    //     panel-pclk-div = <28>; //pixel clock = Peri_pll/(pclk_div+1)
    //     panel-dsi-num-lane = <1>; //0-3: 1lane-4lane
    //     //0-3: data0-data3, 4: clk
    //     panel-dsi-txd0 = <0>;
    //     panel-dsi-txd1 = <1>;
    //     panel-dsi-txd2 = <4>;
    //     panel-dsi-txd3 = <2>;
    //     panel-dsi-txd4 = <3>;
    //     panel-dsi-noncontinuous-clk = <1>; //0:continuous,1:noncontinuous
    //     panel-dsi-t-pre = <1>; //t-pre, >=1
    //     panel-dsi-t-post = <1>; //t-post=tlpx+t-prepare+t-zero+t-pre, >=1
    //     panel-dsi-tx-gap = <1>; //ths-exit
    //     panel-dsi-autoinsert-eotp = <0>; //0:not insert,1:auto-insert
    //     panel-dsi-htx-to-count = <0xFFFFFF>; //high speed TX timeout count
    //     panel-dsi-lrx-to-count = <0xFFFFFF>; //Low power RX timeout count
    //     panel-dsi-bta-to-count = <0xFFFFFF>; //Bus turn around timeout count
    //     panel-dsi-t-wakeup = <0xc8>; //DPHY T-wakeup time
    //     panel-dsi-pix-fifo-send-level = <480>; //buffer send level <= 512
    //     //0-2:16-bit config 1-3; 3-4:18-bit config 1-2; 5:24-bit
    //     panel-dsi-if-color-coding = <0x05>;
    //     //0:16-bit;1:18-bit;2:18-bit loosely packed;3:24-bit
    //     panel-dsi-pix-format = <0x03>;
    //     panel-dsi-vsync-pol = <0>; //0:active low; 1:active high
    //     panel-dsi-hsync-pol = <0>; //0:active low; 1:active high
    //     //0:Non-burst mode with sync pulses;
    //     //1:Noe-burst mode with sync events;
    //     //2:Burst mode; 3:reserved
    //     panel-dsi-video-mode = <1>;
    //     panel-dsi-hfp = <30>; //H front porch blanking packet payload size in bytes
    //     panel-dsi-hbp = <30>; //H back porch blanking packet payload size in bytes
    //     panel-dsi-hsa = <10>; //H sync width blanking packet payload size in bytes
    //     panel-dsi-mult-pkts-en = <0>; //0: single packet;1: two packets
    //     panel-dsi-vbp = <15>; //V back porch lines
    //     panel-dsi-vfp = <12>; //V front porch lines
    //     panel-dsi-vsa = <4>;
    //     //0:blanking packets send during BLLP;1:LP mode used for BLLP
    //     panel-dsi-bllp-mode = <1>;
    //     panel-dsi-use-null-pkt-bllp = <0>; //0:blanking packet; 1:Null packet
    //     panel-dsi-vc = <0x00>; //Virtual channel
    //     panel-dsi-cmd-type = <0x0>; //0:send in LP mode, 1:send in HS mode
    //     panel-dsi-clk = <325>;
    //     /*add special config list here*/
    //     panel-init-list = <  
    //         0x00 0x15 0xEF 0x08 0xFFF
    //         0x00 0x39 0xFF 0x77 0x01 0x00 0x00 0x10 0xFFF
    //         0x00 0x39 0xC0 0x3B 0x00 0xFFF
    //         0x00 0x39 0xC1 0x0D 0x02 0xFFF
    //         0x00 0x39 0xC2 0x21 0x08 0xFFF
    //         0x00 0x39 0xB0 0x00 0x11 0x18 0x0E 0x11 0x06 0x07 0x08 0x07 0x22 0x04 0x12 0x0F 0xAA 0x31 0x18 0xFFF
    //         0x00 0x39 0xB1 0x00 0x11 0x19 0x0E 0x12 0x07 0x08 0x08 0x08 0x22 0x04 0x11 0x11 0xA9 0x32 0x18 0xFFF
    //         0x00 0x39 0xFF 0x77 0x01 0x00 0x00 0x11 0xFFF
    //         0x00 0x15 0xB0 0x60 0xFFF
    //         0x00 0x15 0xB1 0x30 0xFFF
    //         0x00 0x15 0xB2 0x87 0xFFF
    //         0x00 0x15 0xB3 0x80 0xFFF
    //         0x00 0x15 0xB5 0x49 0xFFF
    //         0x00 0x15 0xB7 0x85 0xFFF
    //         0x00 0x15 0xB8 0x21 0xFFF
    //         0x00 0x15 0xC1 0x78 0xFFF
    //         0x14 0x15 0xC2 0x78 0xFFF
    //         0x00 0x39 0xE0 0x00 0x1B 0x02 0xFFF
    //         0x00 0x39 0xE1 0x08 0xA0 0x00 0x00 0x07 0xA0 0x00 0x00 0x00 0x44 0x44 0xFFF
    //         0x00 0x39 0xE2 0x11 0x11 0x44 0x44 0xED 0xA0 0x00 0x00 0xEC 0xA0 0x00 0x00 0xFFF
    //         0x00 0x39 0xE3 0x00 0x00 0x11 0x11 0xFFF
    //         0x00 0x39 0xE4 0x44 0x44 0xFFF
    //         0x00 0x39 0xE5 0x0A 0xE9 0xD8 0xA0 0x0C 0xEB 0xD8 0xA0 0x0E 0xED 0xD8 0xA0 0x10 0xEF 0xD8 0xA0 0xFFF
    //         0x00 0x39 0xE6 0x00 0x00 0x11 0x11 0xFFF
    //         0x00 0x39 0xE7 0x44 0x44 0xFFF
    //         0x00 0x39 0xE8 0x09 0xE8 0xD8 0xA0 0x0B 0xEA 0xD8 0xA0 0x0D 0xEC 0xD8 0xA0 0x0F 0xEE 0xD8 0xA0 0xFFF
    //         0x00 0x39 0xEB 0x02 0x00 0xE4 0xE4 0x88 0x00 0x40 0xFFF
    //         0x00 0x39 0xEC 0x3C 0x00 0xFFF
    //         0x00 0x39 0xED 0xAB 0x89 0x76 0x54 0x02 0xFF 0xFF 0xFF 0xFF 0xFF 0xFF 0x20 0x45 0x67 0x98 0xBA 0xFFF
    //         0x00 0x39 0xEF 0x08 0x08 0x08 0x45 0x3F 0x54 0xFFF
    //         0x00 0x39 0xFF 0x77 0x01 0x00 0x00 0x13 0xFFF
    //         0x00 0x39 0xE8 0x00 0x0E 0xFFF
    //         0xC8 0x05 0x11 0xFFF
    //         0x14 0x39 0xE8 0x00 0x0C 0xFFF
    //         0x00 0x39 0xE8 0x00 0x00 0xFFF
    //         0x00 0x39 0xFF 0x77 0x01 0x00 0x00 0x00 0xFFF
    //         0x96 0x05 0x29 0xFFF>;
    //     status = "disable";
    // };

    // MIPI_35INCH_IPS_640X480: lcd-panel@2 { //for JD9364 MIPI panel setting
    //     compatible = "MIPI_35INCH_IPS_640X480";
    //     panel-if = <1>; //0 for RGB, 1 for MIPI, 2 for MPU
    //     panel-rgb-seq = <1>; //0 for BGR, 1 for RGB
    //     panel-width = <640>;
    //     panel-height = <480>;
    //     panel-pclk-div = <15>; //pixel clock = Peri_pll/(pclk_div+1)
    //     panel-dsi-num-lane = <1>; //0-3: 1lane-4lane
    //     //0-3: data0-data3, 4: clk
    //     panel-dsi-txd0 = <0>;
    //     panel-dsi-txd1 = <1>;
    //     panel-dsi-txd2 = <4>;
    //     panel-dsi-txd3 = <2>;
    //     panel-dsi-txd4 = <3>;
    //     panel-dsi-noncontinuous-clk = <0>; //0:continuous,1:noncontinuous
    //     panel-dsi-t-pre = <1>; //t-pre, >=1
    //     panel-dsi-t-post = <1>; //t-post=tlpx+t-prepare+t-zero+t-pre, >=1
    //     panel-dsi-tx-gap = <1>; //ths-exit
    //     panel-dsi-autoinsert-eotp = <0>; //0:not insert,1:auto-insert
    //     panel-dsi-htx-to-count = <0xFFFFFF>; //high speed TX timeout count
    //     panel-dsi-lrx-to-count = <0xFFFFFF>; //Low power RX timeout count
    //     panel-dsi-bta-to-count = <0xFFFFFF>; //Bus turn around timeout count
    //     panel-dsi-t-wakeup = <0xc8>; //DPHY T-wakeup time
    //     panel-dsi-pix-fifo-send-level = <512>; //buffer send level <= 512
    //     //0-2:16-bit config 1-3; 3-4:18-bit config 1-2; 5:24-bit
    //     panel-dsi-if-color-coding = <0x05>;
    //     //0:16-bit;1:18-bit;2:18-bit loosely packed;3:24-bit
    //     panel-dsi-pix-format = <0x03>;
    //     panel-dsi-vsync-pol = <0>; //0:active low; 1:active high
    //     panel-dsi-hsync-pol = <0>; //0:active low; 1:active high
    //     //0:Non-burst mode with sync pulses;
    //     //1:Noe-burst mode with sync events;
    //     //2:Burst mode; 3:reserved
    //     panel-dsi-video-mode = <2>;
    //     panel-dsi-hfp = <188>; //H front porch blanking packet payload size in bytes
    //     panel-dsi-hbp = <186>; //H back porch blanking packet payload size in bytes
    //     panel-dsi-hsa = <20>; //H sync width blanking packet payload size in bytes
    //     panel-dsi-mult-pkts-en = <0>; //0: single packet;1: two packets
    //     panel-dsi-vbp = <6>; //V back porch lines
    //     panel-dsi-vfp = <11>; //V front porch lines
    //     panel-dsi-vsa = <2>;
    //     //0:blanking packets send during BLLP;1:LP mode used for BLLP
    //     panel-dsi-bllp-mode = <1>;
    //     panel-dsi-use-null-pkt-bllp = <0>; //0:blanking packet; 1:Null packet
    //     panel-dsi-vc = <0x00>; //Virtual channel
    //     panel-dsi-cmd-type = <0x0>; //0:send in LP mode, 1:send in HS mode
    //     panel-dsi-clk = <375>;
    //     /*add special config list here*/
    //     panel-init-list = <  
    //         0x00 0x15 0xE0 0x00 0xFFF
    //         0x00 0x15 0xE1 0x93 0xFFF
    //         0x00 0x15 0xE2 0x65 0xFFF
    //         0x00 0x15 0xE3 0xF8 0xFFF
    //         0x00 0x15 0x80 0x01 0xFFF
    //         0x00 0x15 0xE0 0x01 0xFFF
    //         0x00 0x15 0x00 0x00 0xFFF
    //         0x00 0x15 0x01 0x56 0xFFF
    //         0x00 0x15 0x0C 0x74 0xFFF
    //         0x00 0x15 0x17 0x00 0xFFF
    //         0x00 0x15 0x18 0xBF 0xFFF
    //         0x00 0x15 0x19 0x01 0xFFF
    //         0x00 0x15 0x1A 0x00 0xFFF
    //         0x00 0x15 0x1B 0xBF 0xFFF
    //         0x00 0x15 0x1C 0x01 0xFFF
    //         0x00 0x15 0x24 0xFE 0xFFF
    //         0x00 0x15 0x37 0x09 0xFFF
    //         0x00 0x15 0x38 0x04 0xFFF
    //         0x00 0x15 0x40 0x03 0xFFF
    //         0x00 0x15 0x41 0x3A 0xFFF
    //         0x00 0x15 0x42 0xA0 0xFFF
    //         0x00 0x15 0x43 0x0D 0xFFF
    //         0x00 0x15 0x44 0x07 0xFFF
    //         0x00 0x15 0x45 0x76 0xFFF
    //         0x00 0x15 0x4B 0x04 0xFFF
    //         0x00 0x15 0x55 0x02 0xFFF
    //         0x00 0x15 0x57 0x69 0xFFF
    //         0x00 0x15 0x5A 0x2D 0xFFF
    //         0x00 0x15 0x5B 0x12 0xFFF
    //         0x00 0x15 0x5D 0x7F 0xFFF
    //         0x00 0x15 0x5E 0x68 0xFFF
    //         0x00 0x15 0x5F 0x57 0xFFF
    //         0x00 0x15 0x60 0x47 0xFFF
    //         0x00 0x15 0x61 0x42 0xFFF
    //         0x00 0x15 0x62 0x32 0xFFF
    //         0x00 0x15 0x63 0x33 0xFFF
    //         0x00 0x15 0x64 0x19 0xFFF
    //         0x00 0x15 0x65 0x2B 0xFFF
    //         0x00 0x15 0x66 0x25 0xFFF
    //         0x00 0x15 0x67 0x20 0xFFF
    //         0x00 0x15 0x68 0x37 0xFFF
    //         0x00 0x15 0x69 0x24 0xFFF
    //         0x00 0x15 0x6A 0x24 0xFFF
    //         0x00 0x15 0x6B 0x1A 0xFFF
    //         0x00 0x15 0x6C 0x1D 0xFFF
    //         0x00 0x15 0x6D 0x16 0xFFF
    //         0x00 0x15 0x6E 0x0F 0xFFF
    //         0x00 0x15 0x6F 0x0C 0xFFF
    //         0x00 0x15 0x70 0x7F 0xFFF
    //         0x00 0x15 0x71 0x68 0xFFF
    //         0x00 0x15 0x72 0x57 0xFFF
    //         0x00 0x15 0x73 0x47 0xFFF
    //         0x00 0x15 0x74 0x42 0xFFF
    //         0x00 0x15 0x75 0x32 0xFFF
    //         0x00 0x15 0x76 0x33 0xFFF
    //         0x00 0x15 0x77 0x19 0xFFF
    //         0x00 0x15 0x78 0x2B 0xFFF
    //         0x00 0x15 0x79 0x25 0xFFF
    //         0x00 0x15 0x7A 0x20 0xFFF
    //         0x00 0x15 0x7B 0x37 0xFFF
    //         0x00 0x15 0x7C 0x24 0xFFF
    //         0x00 0x15 0x7D 0x24 0xFFF
    //         0x00 0x15 0x7E 0x1A 0xFFF
    //         0x00 0x15 0x7F 0x1D 0xFFF
    //         0x00 0x15 0x80 0x16 0xFFF
    //         0x00 0x15 0x81 0x0F 0xFFF
    //         0x00 0x15 0x82 0x0C 0xFFF
    //         0x00 0x15 0xE0 0x02 0xFFF
    //         0x00 0x15 0x00 0x5D 0xFFF
    //         0x00 0x15 0x01 0x5D 0xFFF
    //         0x00 0x15 0x02 0x5F 0xFFF
    //         0x00 0x15 0x03 0x5F 0xFFF
    //         0x00 0x15 0x04 0x57 0xFFF
    //         0x00 0x15 0x05 0x58 0xFFF
    //         0x00 0x15 0x06 0x4A 0xFFF
    //         0x00 0x15 0x07 0x44 0xFFF
    //         0x00 0x15 0x08 0x46 0xFFF
    //         0x00 0x15 0x09 0x48 0xFFF
    //         0x00 0x15 0x0A 0x40 0xFFF
    //         0x00 0x15 0x0B 0x5D 0xFFF
    //         0x00 0x15 0x0C 0x5F 0xFFF
    //         0x00 0x15 0x0D 0x5F 0xFFF
    //         0x00 0x15 0x0E 0x5F 0xFFF
    //         0x00 0x15 0x0F 0x5F 0xFFF
    //         0x00 0x15 0x10 0x5F 0xFFF
    //         0x00 0x15 0x11 0x5F 0xFFF
    //         0x00 0x15 0x12 0x5F 0xFFF
    //         0x00 0x15 0x13 0x5F 0xFFF
    //         0x00 0x15 0x14 0x5F 0xFFF
    //         0x00 0x15 0x15 0x5F 0xFFF
    //         0x00 0x15 0x16 0x5D 0xFFF
    //         0x00 0x15 0x17 0x5D 0xFFF
    //         0x00 0x15 0x18 0x5F 0xFFF
    //         0x00 0x15 0x19 0x5F 0xFFF
    //         0x00 0x15 0x1A 0x57 0xFFF
    //         0x00 0x15 0x1B 0x58 0xFFF
    //         0x00 0x15 0x1C 0x4B 0xFFF
    //         0x00 0x15 0x1D 0x45 0xFFF
    //         0x00 0x15 0x1E 0x47 0xFFF
    //         0x00 0x15 0x1F 0x49 0xFFF
    //         0x00 0x15 0x20 0x41 0xFFF
    //         0x00 0x15 0x21 0x5D 0xFFF
    //         0x00 0x15 0x22 0x5F 0xFFF
    //         0x00 0x15 0x23 0x5F 0xFFF
    //         0x00 0x15 0x24 0x5F 0xFFF
    //         0x00 0x15 0x25 0x5F 0xFFF
    //         0x00 0x15 0x26 0x5F 0xFFF
    //         0x00 0x15 0x27 0x5F 0xFFF
    //         0x00 0x15 0x28 0x5F 0xFFF
    //         0x00 0x15 0x29 0x5F 0xFFF
    //         0x00 0x15 0x2A 0x5F 0xFFF
    //         0x00 0x15 0x2B 0x5F 0xFFF
    //         0x00 0x15 0x58 0x40 0xFFF
    //         0x00 0x15 0x59 0x00 0xFFF
    //         0x00 0x15 0x5A 0x00 0xFFF
    //         0x00 0x15 0x5B 0x10 0xFFF
    //         0x00 0x15 0x5C 0x04 0xFFF
    //         0x00 0x15 0x5D 0x20 0xFFF
    //         0x00 0x15 0x5E 0x01 0xFFF
    //         0x00 0x15 0x5F 0x02 0xFFF
    //         0x00 0x15 0x60 0x10 0xFFF
    //         0x00 0x15 0x61 0x01 0xFFF
    //         0x00 0x15 0x62 0x02 0xFFF
    //         0x00 0x15 0x63 0x40 0xFFF
    //         0x00 0x15 0x64 0x48 0xFFF
    //         0x00 0x15 0x65 0x15 0xFFF
    //         0x00 0x15 0x66 0x0C 0xFFF
    //         0x00 0x15 0x67 0x72 0xFFF
    //         0x00 0x15 0x68 0x06 0xFFF
    //         0x00 0x15 0x69 0x60 0xFFF
    //         0x00 0x15 0x6A 0x40 0xFFF
    //         0x00 0x15 0x6B 0x18 0xFFF
    //         0x00 0x15 0x75 0x87 0xFFF
    //         0x00 0x15 0x76 0x02 0xFFF
    //         0x00 0x15 0x77 0x0A 0xFFF
    //         0x00 0x15 0x78 0x3A 0xFFF
    //         0x00 0x15 0x8F 0xE0 0xFFF
    //         0x00 0x15 0x90 0x04 0xFFF
    //         0x00 0x15 0x91 0x08 0xFFF
    //         0x00 0x15 0x92 0x08 0xFFF
    //         0x00 0x15 0xE0 0x04 0xFFF
    //         0x00 0x15 0x00 0x0E 0xFFF
    //         0x00 0x15 0x02 0xB3 0xFFF
    //         0x00 0x15 0x09 0x60 0xFFF
    //         0x00 0x15 0x0E 0x48 0xFFF
    //         0x00 0x15 0xE0 0x00 0xFFF
    //         0x96 0x05 0x11 0xFFF
    //         0x32 0x05 0x29 0xFFF>;
    //     status = "disable";
    // };

    // MIPI_7INCH_IPS_1024X600: lcd-panel@2 { //for JD9364 MIPI panel setting
    //     compatible = "MIPI_7INCH_IPS_1024X600";
    //     panel-if = <1>; //0 for RGB, 1 for MIPI, 2 for MPU
    //     panel-rgb-seq = <1>; //0 for BGR, 1 for RGB
    //     panel-width = <1024>;
    //     panel-height = <600>;
    //     panel-pclk-div = <9>; //pixel clock = Peri_pll/(pclk_div+1)
    //     panel-dsi-num-lane = <3>; //0-3: 1lane-4lane
    //     //0-3: data0-data3, 4: clk
    //     panel-dsi-txd0 = <0>;
    //     panel-dsi-txd1 = <1>;
    //     panel-dsi-txd2 = <4>;
    //     panel-dsi-txd3 = <2>;
    //     panel-dsi-txd4 = <3>;
    //     panel-dsi-noncontinuous-clk = <1>; //0:continuous,1:noncontinuous
    //     panel-dsi-t-pre = <1>; //t-pre, >=1
    //     panel-dsi-t-post = <1>; //t-post=tlpx+t-prepare+t-zero+t-pre, >=1
    //     panel-dsi-tx-gap = <1>; //ths-exit
    //     panel-dsi-autoinsert-eotp = <0>; //0:not insert,1:auto-insert
    //     panel-dsi-htx-to-count = <0xFFFFFF>; //high speed TX timeout count
    //     panel-dsi-lrx-to-count = <0xFFFFFF>; //Low power RX timeout count
    //     panel-dsi-bta-to-count = <0xFFFFFF>; //Bus turn around timeout count
    //     panel-dsi-t-wakeup = <0xc8>; //DPHY T-wakeup time
    //     panel-dsi-pix-fifo-send-level = <512>; //buffer send level <= 512
    //     //0-2:16-bit config 1-3; 3-4:18-bit config 1-2; 5:24-bit
    //     panel-dsi-if-color-coding = <0x05>;
    //     //0:16-bit;1:18-bit;2:18-bit loosely packed;3:24-bit
    //     panel-dsi-pix-format = <0x03>;
    //     panel-dsi-vsync-pol = <0>; //0:active low; 1:active high
    //     panel-dsi-hsync-pol = <0>; //0:active low; 1:active high
    //     //0:Non-burst mode with sync pulses;
    //     //1:Noe-burst mode with sync events;
    //     //2:Burst mode; 3:reserved
    //     panel-dsi-video-mode = <1>;
    //     panel-dsi-hfp = <160>; //H front porch blanking packet payload size in bytes
    //     panel-dsi-hbp = <160>; //H back porch blanking packet payload size in bytes
    //     panel-dsi-hsa = <70>; //H sync width blanking packet payload size in bytes
    //     panel-dsi-mult-pkts-en = <0>; //0: single packet;1: two packets
    //     panel-dsi-vbp = <23>; //V back porch lines
    //     panel-dsi-vfp = <12>; //V front porch lines
    //     panel-dsi-vsa = <10>;
    //     //0:blanking packets send during BLLP;1:LP mode used for BLLP
    //     panel-dsi-bllp-mode = <1>;
    //     panel-dsi-use-null-pkt-bllp = <0>; //0:blanking packet; 1:Null packet
    //     panel-dsi-vc = <0x00>; //Virtual channel
    //     panel-dsi-cmd-type = <0x0>; //0:send in LP mode, 1:send in HS mode
    //     panel-dsi-clk = <600>;
    //     /*add special config list here*/
    //     panel-init-list = <  
    //         >;
    //     status = "disable";
    // };

    // RGB_43INCH_IPS_800X480: lcd-panel@2 { //for RGB panel setting
    //     compatible = "RGB_7INCH_IPS_800X480";
    //     panel-if = <0>; //0 for RGB, 1 for MIPI, 2 for MPU
    //     panel-rgb-seq = <0>; //0 for BGR, 1 for RGB
    //     panel-width = <800>;
    //     panel-height = <480>;
    //     panel-pclk-div = <19>; //pixel clock = Peri_pll/(pclk_div+1)
    //     panel-thpw = <48>;
    //     panel-thb = <40>;
    //     panel-thf = <40>;
    //     panel-tvpw = <1>;
    //     panel-tvb = <31>;
    //     panel-tvf = <13>;
    //     panel-pclk-pol = <0>; //0:pos, 1:neg
    //     panel-hsync-pol = <1>;
    //     panel-vsync-pol = <1>;
    //     panel-vogate-pol = <0>;
    //     panel-bus-width = <3>; //0:8bits,1:16bits,2:18bits,3:24bits
    //     panel-sync-mode = <1>; 

    //     status = "disable";
    // };

    // RGB_7INCH_IPS_800X480: lcd-panel@2 { //for RGB panel setting
    //     compatible = "RGB_7INCH_IPS_800X480";
    //     panel-if = <0>; //0 for RGB, 1 for MIPI, 2 for MPU
    //     panel-rgb-seq = <0>; //0 for BGR, 1 for RGB
    //     panel-width = <800>;
    //     panel-height = <480>;
    //     panel-pclk-div = <14>; //pixel clock = Peri_pll/(pclk_div+1)
    //     panel-thpw = <4>;
    //     panel-thb = <46>;
    //     panel-thf = <210>;
    //     panel-tvpw = <4>;
    //     panel-tvb = <23>;
    //     panel-tvf = <22>;
    //     panel-pclk-pol = <0>; //0:pos, 1:neg
    //     panel-hsync-pol = <1>;
    //     panel-vsync-pol = <1>;
    //     panel-vogate-pol = <0>;
    //     panel-bus-width = <3>; //0:8bits,1:16bits,2:18bits,3:24bits
    //     panel-sync-mode = <1>; 

    //     status = "disable";
    // };

    RGB_101INCH_IPS_1024X600: lcd-panel@2 { //for RGB panel setting
        compatible = "RGB_101INCH_IPS_1024X600";
        panel-if = <0>; //0 for RGB, 1 for MIPI, 2 for MPU
        panel-rgb-seq = <0>; //0 for BGR, 1 for RGB
        panel-width = <1024>;
        panel-height = <600>;
        panel-pclk-div = <9>; //pixel clock = Peri_pll/(pclk_div+1)
        panel-thpw = <10>;
        panel-thb = <160>;
        panel-thf = <150>;
        panel-tvpw = <2>;
        panel-tvb = <23>;
        panel-tvf = <10>;
        panel-pclk-pol = <0>; //0:pos, 1:neg
        panel-hsync-pol = <1>;
        panel-vsync-pol = <1>;
        panel-vogate-pol = <0>;
        panel-bus-width = <3>; //0:8bits,1:16bits,2:18bits,3:24bits
        panel-sync-mode = <1>; 

        status = "disable";
    };


	st7272a: lcd-panel@15 { //for RGB panel setting
		compatible = "sat,sat070cp50";
		panel-if = <0>; //0 for RGB, 1 for MIPI, 2 for MPU
		panel-rgb-seq = <1>; //0 for BGR, 1 for RGB
		panel-width = <320>;
		panel-height = <240>;
		panel-pclk-div = <30>; //pixel clock = Peri_pll(600M)/(pclk_div+1)
		panel-thpw = <4>;
		panel-thb = <43>;
		panel-thf = <8>;
		panel-tvpw = <4>;
		panel-tvb = <12>;
		panel-tvf = <8>;
		panel-pclk-pol = <0>; //0:pos, 1:neg
		panel-hsync-pol = <1>;
		panel-vsync-pol = <1>;
		panel-vogate-pol = <1>;
		panel-bus-width = <0>; //0:8bits,1:16bits,2:18bits,3:24bits
		panel-sync-mode = <1>;
		panel-thd = <960>;
		panel-tvd = <720>;
		status = "disable";
	};

};
